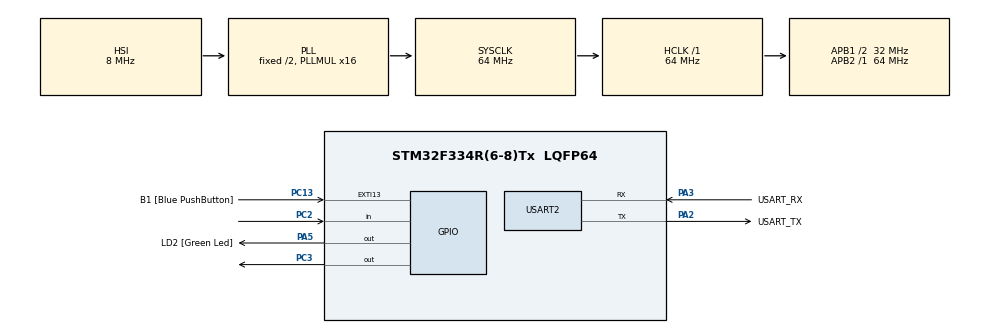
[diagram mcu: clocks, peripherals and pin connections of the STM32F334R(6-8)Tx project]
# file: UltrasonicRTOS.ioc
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FREERTOS.Mutexes01=myMutex01,Dynamic,NULL
FREERTOS.Tasks01=TaskUltrasonic,0,128,Task_ultrasonic,Default,NULL,Dynamic,NULL,NULL;TaskSerial,-3,128,Task_Serial,Default,NULL,Dynamic,NULL,NULL
FREERTOS.configUSE_TIMERS=0
Mcu.Family=STM32F3
Mcu.Name=STM32F334R(6-8)Tx
Mcu.Package=LQFP64
NVIC.PriorityGroup=NVIC_PRIORITYGROUP_4
NVIC.TIM1_BRK_TIM15_IRQn=true\:5\:0\:false\:false\:true\:true\:true
NVIC.TIM3_IRQn=true\:0\:0\:false\:false\:true\:false\:false
NVIC.TimeBase=TIM3_IRQn
NVIC.TimeBaseIP=TIM3
PA13.GPIO_Label=TMS
PA13.Mode=Serial_Wire
PA13.Signal=SYS_JTMS-SWDIO
PA14.GPIO_Label=TCK
PA14.Mode=Serial_Wire
PA14.Signal=SYS_JTCK-SWCLK
PA2.GPIO_Label=USART_TX
PA2.Mode=Asynchronous
PA2.Signal=USART2_TX
PA3.GPIO_Label=USART_RX
PA3.Mode=Asynchronous
PA3.Signal=USART2_RX
PA5.GPIO_Label=LD2 [Green Led]
PA5.Signal=GPIO_Output
PB3.GPIO_Label=SWO
PB3.Signal=SYS_JTDO-TRACESWO
PC13.GPIO_Label=B1 [Blue PushButton]
PC13.GPIO_ModeDefaultEXTI=GPIO_MODE_IT_FALLING
PC13.Signal=GPXTI13
PC14\ /\ OSC32_IN.Mode=LSE-External-Oscillator
PC14\ /\ OSC32_IN.Signal=RCC_OSC32_IN
PC15\ /\ OSC32_OUT.GPIO_Label=RCC_OSC32_OUT
PC15\ /\ OSC32_OUT.Mode=LSE-External-Oscillator
PC15\ /\ OSC32_OUT.Signal=RCC_OSC32_OUT
PC2.Signal=GPIO_Input
PC3.Signal=GPIO_Output
PF0\ /\ OSC_IN.Mode=HSE-External-Clock-Source
PF0\ /\ OSC_IN.Signal=RCC_OSC_IN
PF1\ /\ OSC_OUT.Signal=RCC_OSC_OUT
ProjectManager.HeapSize=0x200
ProjectManager.StackSize=0x400
ProjectManager.TargetToolchain=TrueSTUDIO
RCC.AHBFreq_Value=64000000
RCC.APB1CLKDivider=RCC_HCLK_DIV2
RCC.APB1Freq_Value=32000000
RCC.APB1TimFreq_Value=64000000
RCC.APB2Freq_Value=64000000
RCC.APB2TimFreq_Value=64000000
RCC.CortexFreq_Value=64000000
RCC.FLatency-AdvancedSettings=FLASH_LATENCY_2
RCC.HCLKFreq_Value=64000000
RCC.HSE_VALUE=8000000
RCC.HSI_VALUE=8000000
RCC.PLLMUL=RCC_PLL_MUL16
RCC.SYSCLKFreq_VALUE=64000000
RCC.SYSCLKSourceVirtual=RCC_SYSCLKSOURCE_PLLCLK
TIM15.Period=2
TIM15.Prescaler=399
USART2.VirtualMode-Asynchronous=VM_ASYNC
VP_FREERTOS_VS_ENABLE.Mode=Enabled
VP_SYS_VS_tim3.Mode=TIM3
VP_TIM15_VS_ClockSourceINT.Mode=Internal
board=NUCLEO-F334R8

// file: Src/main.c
/* USER CODE BEGIN Header */
/**
  ******************************************************************************
  * @file           : main.c
  * @brief          : Main program body
  ******************************************************************************
  * This notice applies to any and all portions of this file
  * that are not between comment pairs USER CODE BEGIN and
  * USER CODE END. Other portions of this file, whether
  * inserted by the user or by software development tools
  * are owned by their respective copyright owners.
  *
  * Copyright (c) 2019 STMicroelectronics International N.V.
  * All rights reserved.
  *
  * Redistribution and use in source and binary forms, with or without
  * modification, are permitted, provided that the following conditions are met:
  *
  * 1. Redistribution of source code must retain the above copyright notice,
  *    this list of conditions and the following disclaimer.
  * 2. Redistributions in binary form must reproduce the above copyright notice,
  *    this list of conditions and the following disclaimer in the documentation
  *    and/or other materials provided with the distribution.
  * 3. Neither the name of STMicroelectronics nor the names of other
  *    contributors to this software may be used to endorse or promote products
  *    derived from this software without specific written permission.
  * 4. This software, including modifications and/or derivative works of this
  *    software, must execute solely and exclusively on microcontroller or
  *    microprocessor devices manufactured by or for STMicroelectronics.
  * 5. Redistribution and use of this software other than as permitted under
  *    this license is void and will automatically terminate your rights under
  *    this license.
  *
  * THIS SOFTWARE IS PROVIDED BY STMICROELECTRONICS AND CONTRIBUTORS "AS IS"
  * AND ANY EXPRESS, IMPLIED OR STATUTORY WARRANTIES, INCLUDING, BUT NOT
  * LIMITED TO, THE IMPLIED WARRANTIES OF MERCHANTABILITY, FITNESS FOR A
  * PARTICULAR PURPOSE AND NON-INFRINGEMENT OF THIRD PARTY INTELLECTUAL PROPERTY
  * RIGHTS ARE DISCLAIMED TO THE FULLEST EXTENT PERMITTED BY LAW. IN NO EVENT
  * SHALL STMICROELECTRONICS OR CONTRIBUTORS BE LIABLE FOR ANY DIRECT, INDIRECT,
  * INCIDENTAL, SPECIAL, EXEMPLARY, OR CONSEQUENTIAL DAMAGES (INCLUDING, BUT NOT
  * LIMITED TO, PROCUREMENT OF SUBSTITUTE GOODS OR SERVICES; LOSS OF USE, DATA,
  * OR PROFITS; OR BUSINESS INTERRUPTION) HOWEVER CAUSED AND ON ANY THEORY OF
  * LIABILITY, WHETHER IN CONTRACT, STRICT LIABILITY, OR TORT (INCLUDING
  * NEGLIGENCE OR OTHERWISE) ARISING IN ANY WAY OUT OF THE USE OF THIS SOFTWARE,
  * EVEN IF ADVISED OF THE POSSIBILITY OF SUCH DAMAGE.
  *
  ******************************************************************************
  */
/* USER CODE END Header */

#include "main.h"
#include "cmsis_os.h"
#include "tim.h"
#include "usart.h"
#include "gpio.h"

void SystemClock_Config(void);
void MX_FREERTOS_Init(void);

int main(void)
{

  /* MCU Configuration--------------------------------------------------------*/

  /* Reset of all peripherals, Initializes the Flash interface and the Systick. */
  HAL_Init();

  /* Configure the system clock */
  SystemClock_Config();

  /* Initialize all configured peripherals */
  MX_GPIO_Init();
  MX_USART2_UART_Init();
  MX_TIM15_Init();

  /* Call init function for freertos objects (in freertos.c) */
  MX_FREERTOS_Init();

  /* Start scheduler */
  osKernelStart();

  /* We should never get here as control is now taken by the scheduler */

  /* Infinite loop */
  while (1)
  {

  }
}

void SystemClock_Config(void)
{
  RCC_OscInitTypeDef RCC_OscInitStruct = {0};
  RCC_ClkInitTypeDef RCC_ClkInitStruct = {0};

  /**Initializes the CPU, AHB and APB busses clocks
  */
  RCC_OscInitStruct.OscillatorType = RCC_OSCILLATORTYPE_HSI;
  RCC_OscInitStruct.HSIState = RCC_HSI_ON;
  RCC_OscInitStruct.HSICalibrationValue = RCC_HSICALIBRATION_DEFAULT;
  RCC_OscInitStruct.PLL.PLLState = RCC_PLL_ON;
  RCC_OscInitStruct.PLL.PLLSource = RCC_PLLSOURCE_HSI;
  RCC_OscInitStruct.PLL.PLLMUL = RCC_PLL_MUL16;
  if (HAL_RCC_OscConfig(&RCC_OscInitStruct) != HAL_OK)
  {
    Error_Handler();
  }
  /**Initializes the CPU, AHB and APB busses clocks
  */
  RCC_ClkInitStruct.ClockType = RCC_CLOCKTYPE_HCLK|RCC_CLOCKTYPE_SYSCLK
                              |RCC_CLOCKTYPE_PCLK1|RCC_CLOCKTYPE_PCLK2;
  RCC_ClkInitStruct.SYSCLKSource = RCC_SYSCLKSOURCE_PLLCLK;
  RCC_ClkInitStruct.AHBCLKDivider = RCC_SYSCLK_DIV1;
  RCC_ClkInitStruct.APB1CLKDivider = RCC_HCLK_DIV2;
  RCC_ClkInitStruct.APB2CLKDivider = RCC_HCLK_DIV1;

  if (HAL_RCC_ClockConfig(&RCC_ClkInitStruct, FLASH_LATENCY_2) != HAL_OK)
  {
    Error_Handler();
  }
}

void HAL_TIM_PeriodElapsedCallback(TIM_HandleTypeDef *htim)
{
  if (htim->Instance == TIM3) {
    HAL_IncTick();
  }
}

void Error_Handler(void)
{
}

/************************ (C) COPYRIGHT STMicroelectronics *****END OF FILE****/

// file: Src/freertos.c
/* USER CODE BEGIN Header */
/**
  ******************************************************************************
  * File Name          : freertos.c
  * Description        : Code for freertos applications
  ******************************************************************************
  * This notice applies to any and all portions of this file
  * that are not between comment pairs USER CODE BEGIN and
  * USER CODE END. Other portions of this file, whether
  * inserted by the user or by software development tools
  * are owned by their respective copyright owners.
  *
  * Copyright (c) 2019 STMicroelectronics International N.V.
  * All rights reserved.
  *
  * Redistribution and use in source and binary forms, with or without
  * modification, are permitted, provided that the following conditions are met:
  *
  * 1. Redistribution of source code must retain the above copyright notice,
  *    this list of conditions and the following disclaimer.
  * 2. Redistributions in binary form must reproduce the above copyright notice,
  *    this list of conditions and the following disclaimer in the documentation
  *    and/or other materials provided with the distribution.
  * 3. Neither the name of STMicroelectronics nor the names of other
  *    contributors to this software may be used to endorse or promote products
  *    derived from this software without specific written permission.
  * 4. This software, including modifications and/or derivative works of this
  *    software, must execute solely and exclusively on microcontroller or
  *    microprocessor devices manufactured by or for STMicroelectronics.
  * 5. Redistribution and use of this software other than as permitted under
  *    this license is void and will automatically terminate your rights under
  *    this license.
  *
  * THIS SOFTWARE IS PROVIDED BY STMICROELECTRONICS AND CONTRIBUTORS "AS IS"
  * AND ANY EXPRESS, IMPLIED OR STATUTORY WARRANTIES, INCLUDING, BUT NOT
  * LIMITED TO, THE IMPLIED WARRANTIES OF MERCHANTABILITY, FITNESS FOR A
  * PARTICULAR PURPOSE AND NON-INFRINGEMENT OF THIRD PARTY INTELLECTUAL PROPERTY
  * RIGHTS ARE DISCLAIMED TO THE FULLEST EXTENT PERMITTED BY LAW. IN NO EVENT
  * SHALL STMICROELECTRONICS OR CONTRIBUTORS BE LIABLE FOR ANY DIRECT, INDIRECT,
  * INCIDENTAL, SPECIAL, EXEMPLARY, OR CONSEQUENTIAL DAMAGES (INCLUDING, BUT NOT
  * LIMITED TO, PROCUREMENT OF SUBSTITUTE GOODS OR SERVICES; LOSS OF USE, DATA,
  * OR PROFITS; OR BUSINESS INTERRUPTION) HOWEVER CAUSED AND ON ANY THEORY OF
  * LIABILITY, WHETHER IN CONTRACT, STRICT LIABILITY, OR TORT (INCLUDING
  * NEGLIGENCE OR OTHERWISE) ARISING IN ANY WAY OUT OF THE USE OF THIS SOFTWARE,
  * EVEN IF ADVISED OF THE POSSIBILITY OF SUCH DAMAGE.
  *
  ******************************************************************************
  */
/* USER CODE END Header */

#include "FreeRTOS.h"
#include "task.h"
#include "main.h"
#include "cmsis_os.h"

#include "tim.h"
#include "usart.h"
#include "gpio.h"

osThreadId TaskUltrasonicHandle;
osThreadId TaskSerialHandle;
osMutexId myMutex01Handle;

void Task_ultrasonic(void const * argument);
void Task_Serial(void const * argument);

void MX_FREERTOS_Init(void); /* (MISRA C 2004 rule 8.1) */

void MX_FREERTOS_Init(void) {

  /* Create the mutex(es) */
  /* definition and creation of myMutex01 */
  osMutexDef(myMutex01);
  myMutex01Handle = osMutexCreate(osMutex(myMutex01));

  /* Create the thread(s) */
  /* definition and creation of TaskUltrasonic */
  osThreadDef(TaskUltrasonic, Task_ultrasonic, osPriorityNormal, 0, 128);
  TaskUltrasonicHandle = osThreadCreate(osThread(TaskUltrasonic), NULL);

  /* definition and creation of TaskSerial */
  osThreadDef(TaskSerial, Task_Serial, osPriorityIdle, 0, 128);
  TaskSerialHandle = osThreadCreate(osThread(TaskSerial), NULL);

}

extern state State_measure;
extern UART_HandleTypeDef huart2;
extern volatile float Medicion;
extern volatile int count;
extern volatile int Medicion_d;

union u_type            //Setup a Union
{
  unsigned int IntVar;
  unsigned char Bytes[4];
}Range;

void Task_ultrasonic(void const * argument)
{

  /* USER CODE BEGIN Task_ultrasonic */
  /* Infinite loop */
  for(;;)
  {
	//semaphore get
	xSemaphoreTake(myMutex01Handle,portMAX_DELAY);
	State_measure = Ready;
	HAL_TIM_Base_Start_IT(&htim15);
	xSemaphoreGive(myMutex01Handle);
	//semaphore free
	HAL_GPIO_TogglePin(GPIOA, GPIO_PIN_5); //heartbeat
    osDelay(30);
  }
  /* USER CODE END Task_ultrasonic */
}

void Task_Serial(void const * argument)
{
  /* USER CODE BEGIN Task_Serial */
  /* Infinite loop */
  uint8_t str[100];
  int len = 0;

  for(;;)
  {
	//semaphore get
	xSemaphoreTake(myMutex01Handle,portMAX_DELAY);
	Range.IntVar = Medicion_d;
	len = sprintf(str,"Range (cm) = %d , %d , %d\n",Medicion_d,Range.Bytes[0],Range.Bytes[1]);//variable compartida
	//semaphore free
	xSemaphoreGive(myMutex01Handle);
	HAL_UART_Transmit(&huart2,str,len , 15);

    osDelay(200);
  }
  /* USER CODE END Task_Serial */
}

/************************ (C) COPYRIGHT STMicroelectronics *****END OF FILE****/
